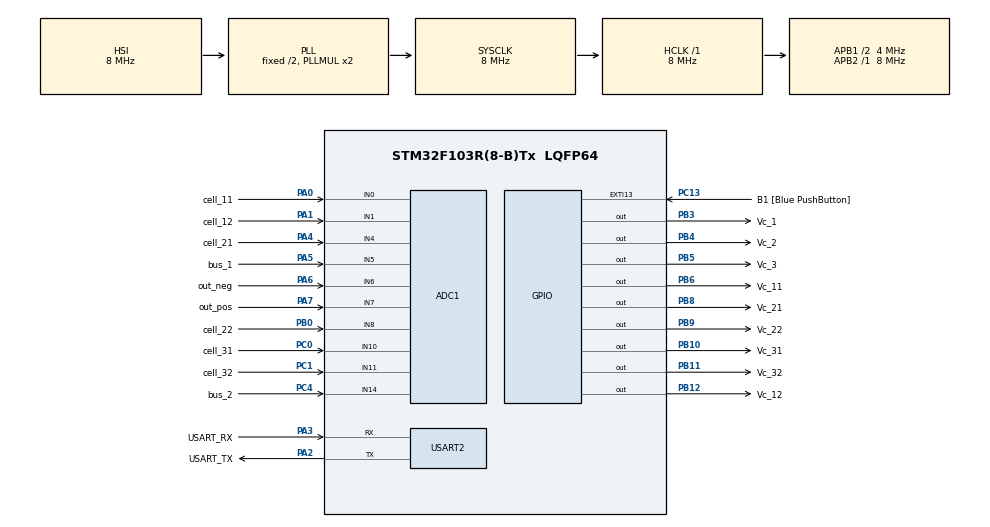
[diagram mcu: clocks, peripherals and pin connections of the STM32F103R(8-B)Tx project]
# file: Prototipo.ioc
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ADC1.Channel-1\#ChannelRegularConversion=ADC_CHANNEL_0
ADC1.Channel-10\#ChannelRegularConversion=ADC_CHANNEL_14
ADC1.Channel-2\#ChannelRegularConversion=ADC_CHANNEL_1
ADC1.Channel-3\#ChannelRegularConversion=ADC_CHANNEL_4
ADC1.Channel-4\#ChannelRegularConversion=ADC_CHANNEL_5
ADC1.Channel-5\#ChannelRegularConversion=ADC_CHANNEL_6
ADC1.Channel-6\#ChannelRegularConversion=ADC_CHANNEL_7
ADC1.Channel-7\#ChannelRegularConversion=ADC_CHANNEL_8
ADC1.Channel-8\#ChannelRegularConversion=ADC_CHANNEL_10
ADC1.Channel-9\#ChannelRegularConversion=ADC_CHANNEL_11
ADC1.ContinuousConvMode=ENABLE
ADC1.NbrOfConversion=10
ADC1.NbrOfConversionFlag=1
ADC1.Rank-1\#ChannelRegularConversion=1
ADC1.Rank-10\#ChannelRegularConversion=10
ADC1.Rank-2\#ChannelRegularConversion=2
ADC1.Rank-3\#ChannelRegularConversion=3
ADC1.Rank-4\#ChannelRegularConversion=4
ADC1.Rank-5\#ChannelRegularConversion=5
ADC1.Rank-6\#ChannelRegularConversion=6
ADC1.Rank-7\#ChannelRegularConversion=7
ADC1.Rank-8\#ChannelRegularConversion=8
ADC1.Rank-9\#ChannelRegularConversion=9
ADC1.SamplingTime-1\#ChannelRegularConversion=ADC_SAMPLETIME_239CYCLES_5
ADC1.SamplingTime-10\#ChannelRegularConversion=ADC_SAMPLETIME_239CYCLES_5
ADC1.SamplingTime-2\#ChannelRegularConversion=ADC_SAMPLETIME_239CYCLES_5
ADC1.SamplingTime-3\#ChannelRegularConversion=ADC_SAMPLETIME_239CYCLES_5
ADC1.SamplingTime-4\#ChannelRegularConversion=ADC_SAMPLETIME_239CYCLES_5
ADC1.SamplingTime-5\#ChannelRegularConversion=ADC_SAMPLETIME_239CYCLES_5
ADC1.SamplingTime-6\#ChannelRegularConversion=ADC_SAMPLETIME_239CYCLES_5
ADC1.SamplingTime-7\#ChannelRegularConversion=ADC_SAMPLETIME_239CYCLES_5
ADC1.SamplingTime-8\#ChannelRegularConversion=ADC_SAMPLETIME_239CYCLES_5
ADC1.SamplingTime-9\#ChannelRegularConversion=ADC_SAMPLETIME_239CYCLES_5
ADC1.master=1
Dma.ADC1.0.Direction=DMA_PERIPH_TO_MEMORY
Dma.ADC1.0.Instance=DMA1_Channel1
Dma.ADC1.0.MemDataAlignment=DMA_MDATAALIGN_HALFWORD
Dma.ADC1.0.MemInc=DMA_MINC_ENABLE
Dma.ADC1.0.Mode=DMA_CIRCULAR
Dma.ADC1.0.PeriphDataAlignment=DMA_PDATAALIGN_HALFWORD
Dma.ADC1.0.PeriphInc=DMA_PINC_DISABLE
Dma.ADC1.0.Priority=DMA_PRIORITY_LOW
Dma.Request0=ADC1
Mcu.Family=STM32F1
Mcu.Name=STM32F103R(8-B)Tx
Mcu.Package=LQFP64
NVIC.ADC1_2_IRQn=true\:0\:0\:false\:false\:true\:true\:true\:true
NVIC.DMA1_Channel1_IRQn=true\:0\:0\:false\:false\:true\:false\:true\:true
NVIC.EXTI15_10_IRQn=true\:0\:0\:false\:false\:true\:true\:true\:true
NVIC.PriorityGroup=NVIC_PRIORITYGROUP_4
NVIC.USART2_IRQn=true\:0\:0\:false\:false\:true\:true\:true\:true
PA0-WKUP.GPIO_Label=cell_11
PA0-WKUP.Signal=ADCx_IN0
PA1.GPIO_Label=cell_12
PA1.Signal=ADCx_IN1
PA13.GPIO_Label=TMS
PA13.Mode=Serial_Wire
PA13.Signal=SYS_JTMS-SWDIO
PA14.GPIO_Label=TCK
PA14.Mode=Serial_Wire
PA14.Signal=SYS_JTCK-SWCLK
PA2.GPIO_Label=USART_TX
PA2.GPIO_Mode=GPIO_MODE_AF_PP
PA2.GPIO_PuPd=GPIO_NOPULL
PA2.GPIO_Speed=GPIO_SPEED_FREQ_LOW
PA2.Mode=Asynchronous
PA2.Signal=USART2_TX
PA3.GPIO_Label=USART_RX
PA3.GPIO_Mode=GPIO_MODE_INPUT
PA3.GPIO_PuPd=GPIO_NOPULL
PA3.GPIO_Speed=GPIO_SPEED_FREQ_LOW
PA3.Mode=Asynchronous
PA3.Signal=USART2_RX
PA4.GPIO_Label=cell_21
PA4.Signal=ADCx_IN4
PA5.GPIO_Label=bus_1
PA5.Signal=ADCx_IN5
PA6.GPIO_Label=out_neg
PA6.Signal=ADCx_IN6
PA7.GPIO_Label=out_pos
PA7.Signal=ADCx_IN7
PB0.GPIO_Label=cell_22
PB0.Signal=ADCx_IN8
PB10.GPIO_Label=Vc_31
PB10.GPIO_PuPd=GPIO_PULLDOWN
PB10.PinState=GPIO_PIN_RESET
PB10.Signal=GPIO_Output
PB11.GPIO_Label=Vc_32
PB11.GPIO_PuPd=GPIO_PULLDOWN
PB11.PinState=GPIO_PIN_RESET
PB11.Signal=GPIO_Output
PB12.GPIO_Label=Vc_12
PB12.GPIO_PuPd=GPIO_PULLDOWN
PB12.PinState=GPIO_PIN_RESET
PB12.Signal=GPIO_Output
PB3.GPIO_Label=Vc_1
PB3.GPIO_ModeDefaultOutputPP=GPIO_MODE_OUTPUT_PP
PB3.GPIO_PuPd=GPIO_PULLDOWN
PB3.PinState=GPIO_PIN_RESET
PB3.Signal=GPIO_Output
PB4.GPIO_Label=Vc_2
PB4.GPIO_ModeDefaultOutputPP=GPIO_MODE_OUTPUT_PP
PB4.GPIO_PuPd=GPIO_PULLDOWN
PB4.PinState=GPIO_PIN_RESET
PB4.Signal=GPIO_Output
PB5.GPIO_Label=Vc_3
PB5.GPIO_ModeDefaultOutputPP=GPIO_MODE_OUTPUT_PP
PB5.GPIO_PuPd=GPIO_PULLDOWN
PB5.PinState=GPIO_PIN_RESET
PB5.Signal=GPIO_Output
PB6.GPIO_Label=Vc_11
PB6.GPIO_PuPd=GPIO_PULLDOWN
PB6.PinState=GPIO_PIN_RESET
PB6.Signal=GPIO_Output
PB8.GPIO_Label=Vc_21
PB8.GPIO_PuPd=GPIO_PULLDOWN
PB8.PinState=GPIO_PIN_RESET
PB8.Signal=GPIO_Output
PB9.GPIO_Label=Vc_22
PB9.GPIO_PuPd=GPIO_PULLDOWN
PB9.PinState=GPIO_PIN_RESET
PB9.Signal=GPIO_Output
PC0.GPIO_Label=cell_31
PC0.Signal=ADCx_IN10
PC1.GPIO_Label=cell_32
PC1.Signal=ADCx_IN11
PC13-TAMPER-RTC.GPIO_Label=B1 [Blue PushButton]
PC13-TAMPER-RTC.GPIO_PuPd=GPIO_NOPULL
PC13-TAMPER-RTC.Signal=GPXTI13
PC14-OSC32_IN.Mode=LSE-External-Oscillator
PC14-OSC32_IN.Signal=RCC_OSC32_IN
PC15-OSC32_OUT.Mode=LSE-External-Oscillator
PC15-OSC32_OUT.Signal=RCC_OSC32_OUT
PC4.GPIO_Label=bus_2
PC4.Signal=ADCx_IN14
PD0-OSC_IN.Mode=HSE-External-Clock-Source
PD0-OSC_IN.Signal=RCC_OSC_IN
PD1-OSC_OUT.Mode=HSE-External-Clock-Source
PD1-OSC_OUT.Signal=RCC_OSC_OUT
ProjectManager.HeapSize=0x200
ProjectManager.StackSize=0x400
ProjectManager.TargetToolchain=STM32CubeIDE
RCC.AHBFreq_Value=8000000
RCC.APB1CLKDivider=RCC_HCLK_DIV2
RCC.APB1Freq_Value=4000000
RCC.APB1TimFreq_Value=8000000
RCC.APB2Freq_Value=8000000
RCC.APB2TimFreq_Value=8000000
RCC.HCLKFreq_Value=8000000
RCC.RTCClockSelection=RCC_RTCCLKSOURCE_LSE
RCC.SYSCLKFreq_VALUE=8000000
RCC.SYSCLKSource=RCC_SYSCLKSOURCE_PLLCLK
RCC.USBFreq_Value=8000000
SH.ADCx_IN0.0=ADC1_IN0,IN0
SH.ADCx_IN1.0=ADC1_IN1,IN1
SH.ADCx_IN10.0=ADC1_IN10,IN10
SH.ADCx_IN11.0=ADC1_IN11,IN11
SH.ADCx_IN14.0=ADC1_IN14,IN14
SH.ADCx_IN4.0=ADC1_IN4,IN4
SH.ADCx_IN5.0=ADC1_IN5,IN5
SH.ADCx_IN6.0=ADC1_IN6,IN6
SH.ADCx_IN7.0=ADC1_IN7,IN7
SH.ADCx_IN8.0=ADC1_IN8,IN8
USART2.VirtualMode=VM_ASYNC
board=NUCLEO-F103RB

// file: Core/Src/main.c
/* USER CODE BEGIN Header */
/**
  ******************************************************************************
  * @file           : main.c
  * @brief          : Main program body
  ******************************************************************************
  * @attention
  *
  * Copyright (c) 2025 STMicroelectronics.
  * All rights reserved.
  *
  * This software is licensed under terms that can be found in the LICENSE file
  * in the root directory of this software component.
  * If no LICENSE file comes with this software, it is provided AS-IS.
  *
  ******************************************************************************
  */
/* USER CODE END Header */
#include "main.h"

/* USER CODE BEGIN Includes */
#include "cli.h"
#include "controller.h"
/* USER CODE END Includes */

ADC_HandleTypeDef hadc1;
DMA_HandleTypeDef hdma_adc1;

UART_HandleTypeDef huart2;

void SystemClock_Config(void);
static void MX_GPIO_Init(void);
static void MX_DMA_Init(void);
static void MX_USART2_UART_Init(void);
static void MX_ADC1_Init(void);

int main(void)
{

  /* MCU Configuration--------------------------------------------------------*/

  /* Reset of all peripherals, Initializes the Flash interface and the Systick. */
  HAL_Init();

  /* Configure the system clock */
  SystemClock_Config();

  /* Initialize all configured peripherals */
  MX_GPIO_Init();
  MX_DMA_Init();
  MX_USART2_UART_Init();
  MX_ADC1_Init();
  /* USER CODE BEGIN 2 */
  CLI_Init(&huart2);
  Controller_Init();
  /* USER CODE END 2 */

  /* Infinite loop */
  while (1)
  {

  }
}

void SystemClock_Config(void)
{
  RCC_OscInitTypeDef RCC_OscInitStruct = {0};
  RCC_ClkInitTypeDef RCC_ClkInitStruct = {0};
  RCC_PeriphCLKInitTypeDef PeriphClkInit = {0};

  /** Initializes the RCC Oscillators according to the specified parameters
  * in the RCC_OscInitTypeDef structure.
  */
  RCC_OscInitStruct.OscillatorType = RCC_OSCILLATORTYPE_HSI;
  RCC_OscInitStruct.HSIState = RCC_HSI_ON;
  RCC_OscInitStruct.HSICalibrationValue = RCC_HSICALIBRATION_DEFAULT;
  RCC_OscInitStruct.PLL.PLLState = RCC_PLL_ON;
  RCC_OscInitStruct.PLL.PLLSource = RCC_PLLSOURCE_HSI_DIV2;
  RCC_OscInitStruct.PLL.PLLMUL = RCC_PLL_MUL2;
  if (HAL_RCC_OscConfig(&RCC_OscInitStruct) != HAL_OK)
  {
    Error_Handler();
  }

  /** Initializes the CPU, AHB and APB buses clocks
  */
  RCC_ClkInitStruct.ClockType = RCC_CLOCKTYPE_HCLK|RCC_CLOCKTYPE_SYSCLK
                              |RCC_CLOCKTYPE_PCLK1|RCC_CLOCKTYPE_PCLK2;
  RCC_ClkInitStruct.SYSCLKSource = RCC_SYSCLKSOURCE_PLLCLK;
  RCC_ClkInitStruct.AHBCLKDivider = RCC_SYSCLK_DIV1;
  RCC_ClkInitStruct.APB1CLKDivider = RCC_HCLK_DIV2;
  RCC_ClkInitStruct.APB2CLKDivider = RCC_HCLK_DIV1;

  if (HAL_RCC_ClockConfig(&RCC_ClkInitStruct, FLASH_LATENCY_0) != HAL_OK)
  {
    Error_Handler();
  }
  PeriphClkInit.PeriphClockSelection = RCC_PERIPHCLK_ADC;
  PeriphClkInit.AdcClockSelection = RCC_ADCPCLK2_DIV2;
  if (HAL_RCCEx_PeriphCLKConfig(&PeriphClkInit) != HAL_OK)
  {
    Error_Handler();
  }
}

static void MX_ADC1_Init(void)
{

  ADC_ChannelConfTypeDef sConfig = {0};

  /** Common config
  */
  hadc1.Instance = ADC1;
  hadc1.Init.ScanConvMode = ADC_SCAN_ENABLE;
  hadc1.Init.ContinuousConvMode = ENABLE;
  hadc1.Init.DiscontinuousConvMode = DISABLE;
  hadc1.Init.ExternalTrigConv = ADC_SOFTWARE_START;
  hadc1.Init.DataAlign = ADC_DATAALIGN_RIGHT;
  hadc1.Init.NbrOfConversion = 10;
  if (HAL_ADC_Init(&hadc1) != HAL_OK)
  {
    Error_Handler();
  }

  /** Configure Regular Channel
  */
  sConfig.Channel = ADC_CHANNEL_0;
  sConfig.Rank = ADC_REGULAR_RANK_1;
  sConfig.SamplingTime = ADC_SAMPLETIME_239CYCLES_5;
  if (HAL_ADC_ConfigChannel(&hadc1, &sConfig) != HAL_OK)
  {
    Error_Handler();
  }

  /** Configure Regular Channel
  */
  sConfig.Channel = ADC_CHANNEL_1;
  sConfig.Rank = ADC_REGULAR_RANK_2;
  if (HAL_ADC_ConfigChannel(&hadc1, &sConfig) != HAL_OK)
  {
    Error_Handler();
  }

  /** Configure Regular Channel
  */
  sConfig.Channel = ADC_CHANNEL_4;
  sConfig.Rank = ADC_REGULAR_RANK_3;
  if (HAL_ADC_ConfigChannel(&hadc1, &sConfig) != HAL_OK)
  {
    Error_Handler();
  }

  /** Configure Regular Channel
  */
  sConfig.Channel = ADC_CHANNEL_5;
  sConfig.Rank = ADC_REGULAR_RANK_4;
  if (HAL_ADC_ConfigChannel(&hadc1, &sConfig) != HAL_OK)
  {
    Error_Handler();
  }

  /** Configure Regular Channel
  */
  sConfig.Channel = ADC_CHANNEL_6;
  sConfig.Rank = ADC_REGULAR_RANK_5;
  if (HAL_ADC_ConfigChannel(&hadc1, &sConfig) != HAL_OK)
  {
    Error_Handler();
  }

  /** Configure Regular Channel
  */
  sConfig.Channel = ADC_CHANNEL_7;
  sConfig.Rank = ADC_REGULAR_RANK_6;
  if (HAL_ADC_ConfigChannel(&hadc1, &sConfig) != HAL_OK)
  {
    Error_Handler();
  }

  /** Configure Regular Channel
  */
  sConfig.Channel = ADC_CHANNEL_8;
  sConfig.Rank = ADC_REGULAR_RANK_7;
  if (HAL_ADC_ConfigChannel(&hadc1, &sConfig) != HAL_OK)
  {
    Error_Handler();
  }

  /** Configure Regular Channel
  */
  sConfig.Channel = ADC_CHANNEL_10;
  sConfig.Rank = ADC_REGULAR_RANK_8;
  if (HAL_ADC_ConfigChannel(&hadc1, &sConfig) != HAL_OK)
  {
    Error_Handler();
  }

  /** Configure Regular Channel
  */
  sConfig.Channel = ADC_CHANNEL_11;
  sConfig.Rank = ADC_REGULAR_RANK_9;
  if (HAL_ADC_ConfigChannel(&hadc1, &sConfig) != HAL_OK)
  {
    Error_Handler();
  }

  /** Configure Regular Channel
  */
  sConfig.Channel = ADC_CHANNEL_14;
  sConfig.Rank = ADC_REGULAR_RANK_10;
  if (HAL_ADC_ConfigChannel(&hadc1, &sConfig) != HAL_OK)
  {
    Error_Handler();
  }

}

static void MX_USART2_UART_Init(void)
{

  huart2.Instance = USART2;
  huart2.Init.BaudRate = 115200;
  huart2.Init.WordLength = UART_WORDLENGTH_8B;
  huart2.Init.StopBits = UART_STOPBITS_1;
  huart2.Init.Parity = UART_PARITY_NONE;
  huart2.Init.Mode = UART_MODE_TX_RX;
  huart2.Init.HwFlowCtl = UART_HWCONTROL_NONE;
  huart2.Init.OverSampling = UART_OVERSAMPLING_16;
  if (HAL_UART_Init(&huart2) != HAL_OK)
  {
    Error_Handler();
  }

}

static void MX_DMA_Init(void)
{

  /* DMA controller clock enable */
  __HAL_RCC_DMA1_CLK_ENABLE();

  /* DMA interrupt init */
  /* DMA1_Channel1_IRQn interrupt configuration */
  HAL_NVIC_SetPriority(DMA1_Channel1_IRQn, 0, 0);
  HAL_NVIC_EnableIRQ(DMA1_Channel1_IRQn);

}

static void MX_GPIO_Init(void)
{
  GPIO_InitTypeDef GPIO_InitStruct = {0};

  /* GPIO Ports Clock Enable */
  __HAL_RCC_GPIOC_CLK_ENABLE();
  __HAL_RCC_GPIOD_CLK_ENABLE();
  __HAL_RCC_GPIOA_CLK_ENABLE();
  __HAL_RCC_GPIOB_CLK_ENABLE();

  /*Configure GPIO pin Output Level */
  HAL_GPIO_WritePin(GPIOB, Vc_31_Pin|Vc_32_Pin|Vc_12_Pin|Vc_1_Pin
                          |Vc_2_Pin|Vc_3_Pin|Vc_11_Pin|Vc_21_Pin
                          |Vc_22_Pin, GPIO_PIN_RESET);

  /*Configure GPIO pin : B1_Pin */
  GPIO_InitStruct.Pin = B1_Pin;
  GPIO_InitStruct.Mode = GPIO_MODE_IT_RISING;
  GPIO_InitStruct.Pull = GPIO_NOPULL;
  HAL_GPIO_Init(B1_GPIO_Port, &GPIO_InitStruct);

  /*Configure GPIO pins : Vc_31_Pin Vc_32_Pin Vc_12_Pin Vc_1_Pin
                           Vc_2_Pin Vc_3_Pin Vc_11_Pin Vc_21_Pin
                           Vc_22_Pin */
  GPIO_InitStruct.Pin = Vc_31_Pin|Vc_32_Pin|Vc_12_Pin|Vc_1_Pin
                          |Vc_2_Pin|Vc_3_Pin|Vc_11_Pin|Vc_21_Pin
                          |Vc_22_Pin;
  GPIO_InitStruct.Mode = GPIO_MODE_OUTPUT_PP;
  GPIO_InitStruct.Pull = GPIO_PULLDOWN;
  GPIO_InitStruct.Speed = GPIO_SPEED_FREQ_LOW;
  HAL_GPIO_Init(GPIOB, &GPIO_InitStruct);

  /* EXTI interrupt init*/
  HAL_NVIC_SetPriority(EXTI15_10_IRQn, 0, 0);
  HAL_NVIC_EnableIRQ(EXTI15_10_IRQn);

}

/* USER CODE BEGIN 4 */
void HAL_UART_RxCpltCallback(UART_HandleTypeDef *huart)
{
  CLI_RxCallback(huart);
}
/* USER CODE END 4 */

void Error_Handler(void)
{
  __disable_irq();
  while (1)
  {
  }
}
